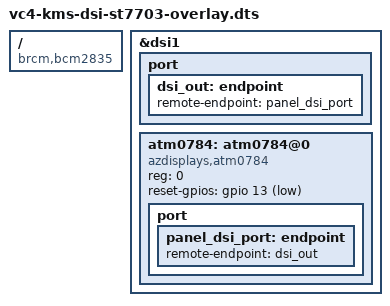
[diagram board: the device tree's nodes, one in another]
/dts-v1/;
/plugin/;

/ {
	compatible = "brcm,bcm2835";

	fragment@0 {
		target = <&dsi1>;
		__overlay__  {
			status = "okay";
			#address-cells = <1>;
			#size-cells = <0>;

			port {
				dsi_out: endpoint {
					remote-endpoint = <&panel_dsi_port>;
				};
			};

			atm0784: atm0784@0 {
				compatible = "azdisplays,atm0784";
                status = "okay";
				reg = <0>;
				// Add a regulator if you have one
				//power-supply = <&reg_display>;
				// Add a backlight controller  if you have one
				//backlight = <&backlight>;
                // Add reset pin
                reset-gpios = <&gpio 13 1>; /* GPIO PIN 13, active Low */

				port {
					panel_dsi_port: endpoint {
						remote-endpoint = <&dsi_out>;
					};
				};
			};
		};
	};
};
